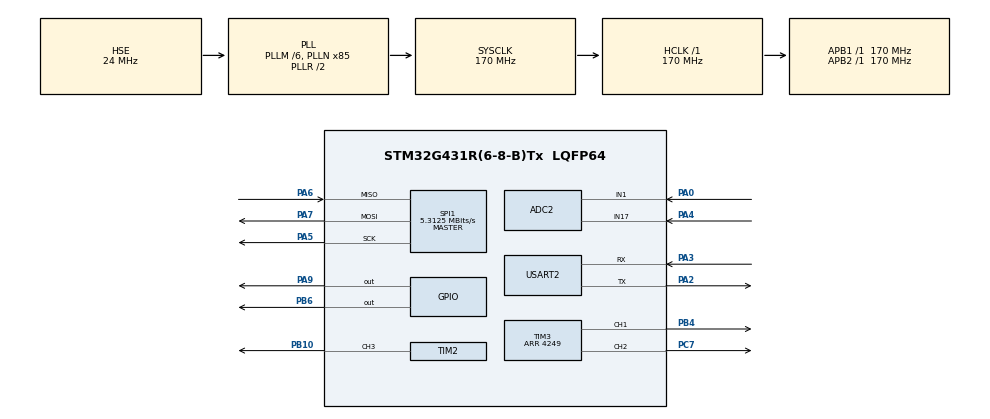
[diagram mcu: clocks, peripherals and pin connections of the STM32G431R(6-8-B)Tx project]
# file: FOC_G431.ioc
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ADC2.Channel-0\#ChannelRegularConversion=ADC_CHANNEL_1
ADC2.Channel-1\#ChannelRegularConversion=ADC_CHANNEL_17
ADC2.DMAContinuousRequests=ENABLE
ADC2.EOCSelection=ADC_EOC_SEQ_CONV
ADC2.ExternalTrigConv=ADC_EXTERNALTRIG_T3_TRGO
ADC2.NbrOfConversion=2
ADC2.NbrOfConversionFlag=1
ADC2.OffsetNumber-0\#ChannelRegularConversion=ADC_OFFSET_NONE
ADC2.OffsetNumber-1\#ChannelRegularConversion=ADC_OFFSET_NONE
ADC2.Rank-0\#ChannelRegularConversion=1
ADC2.Rank-1\#ChannelRegularConversion=2
ADC2.SamplingTime-0\#ChannelRegularConversion=ADC_SAMPLETIME_92CYCLES_5
ADC2.SamplingTime-1\#ChannelRegularConversion=ADC_SAMPLETIME_92CYCLES_5
Dma.ADC2.3.Direction=DMA_PERIPH_TO_MEMORY
Dma.ADC2.3.EventEnable=DISABLE
Dma.ADC2.3.Instance=DMA1_Channel4
Dma.ADC2.3.MemDataAlignment=DMA_MDATAALIGN_HALFWORD
Dma.ADC2.3.MemInc=DMA_MINC_ENABLE
Dma.ADC2.3.Mode=DMA_CIRCULAR
Dma.ADC2.3.PeriphDataAlignment=DMA_PDATAALIGN_HALFWORD
Dma.ADC2.3.PeriphInc=DMA_PINC_DISABLE
Dma.ADC2.3.Polarity=HAL_DMAMUX_REQ_GEN_RISING
Dma.ADC2.3.Priority=DMA_PRIORITY_LOW
Dma.ADC2.3.RequestNumber=1
Dma.ADC2.3.SignalID=NONE
Dma.ADC2.3.SyncEnable=DISABLE
Dma.ADC2.3.SyncPolarity=HAL_DMAMUX_SYNC_NO_EVENT
Dma.ADC2.3.SyncRequestNumber=1
Dma.ADC2.3.SyncSignalID=NONE
Dma.Request0=SPI1_RX
Dma.Request1=SPI1_TX
Dma.Request2=USART2_TX
Dma.Request3=ADC2
Dma.SPI1_RX.0.Direction=DMA_PERIPH_TO_MEMORY
Dma.SPI1_RX.0.EventEnable=DISABLE
Dma.SPI1_RX.0.Instance=DMA1_Channel1
Dma.SPI1_RX.0.MemDataAlignment=DMA_MDATAALIGN_HALFWORD
Dma.SPI1_RX.0.MemInc=DMA_MINC_ENABLE
Dma.SPI1_RX.0.Mode=DMA_NORMAL
Dma.SPI1_RX.0.PeriphDataAlignment=DMA_PDATAALIGN_HALFWORD
Dma.SPI1_RX.0.PeriphInc=DMA_PINC_DISABLE
Dma.SPI1_RX.0.Polarity=HAL_DMAMUX_REQ_GEN_RISING
Dma.SPI1_RX.0.Priority=DMA_PRIORITY_LOW
Dma.SPI1_RX.0.RequestNumber=1
Dma.SPI1_RX.0.SignalID=NONE
Dma.SPI1_RX.0.SyncEnable=ENABLE
Dma.SPI1_RX.0.SyncPolarity=HAL_DMAMUX_SYNC_RISING
Dma.SPI1_RX.0.SyncRequestNumber=1
Dma.SPI1_RX.0.SyncSignalID=NONE
Dma.SPI1_TX.1.Direction=DMA_MEMORY_TO_PERIPH
Dma.SPI1_TX.1.EventEnable=DISABLE
Dma.SPI1_TX.1.Instance=DMA1_Channel2
Dma.SPI1_TX.1.MemDataAlignment=DMA_MDATAALIGN_HALFWORD
Dma.SPI1_TX.1.MemInc=DMA_MINC_ENABLE
Dma.SPI1_TX.1.Mode=DMA_NORMAL
Dma.SPI1_TX.1.PeriphDataAlignment=DMA_PDATAALIGN_HALFWORD
Dma.SPI1_TX.1.PeriphInc=DMA_PINC_DISABLE
Dma.SPI1_TX.1.Polarity=HAL_DMAMUX_REQ_GEN_RISING
Dma.SPI1_TX.1.Priority=DMA_PRIORITY_LOW
Dma.SPI1_TX.1.RequestNumber=1
Dma.SPI1_TX.1.SignalID=NONE
Dma.SPI1_TX.1.SyncEnable=ENABLE
Dma.SPI1_TX.1.SyncPolarity=HAL_DMAMUX_SYNC_RISING
Dma.SPI1_TX.1.SyncRequestNumber=1
Dma.SPI1_TX.1.SyncSignalID=NONE
Dma.USART2_TX.2.Direction=DMA_MEMORY_TO_PERIPH
Dma.USART2_TX.2.EventEnable=DISABLE
Dma.USART2_TX.2.Instance=DMA1_Channel3
Dma.USART2_TX.2.MemDataAlignment=DMA_MDATAALIGN_BYTE
Dma.USART2_TX.2.MemInc=DMA_MINC_ENABLE
Dma.USART2_TX.2.Mode=DMA_NORMAL
Dma.USART2_TX.2.PeriphDataAlignment=DMA_PDATAALIGN_BYTE
Dma.USART2_TX.2.PeriphInc=DMA_PINC_DISABLE
Dma.USART2_TX.2.Polarity=HAL_DMAMUX_REQ_GEN_RISING
Dma.USART2_TX.2.Priority=DMA_PRIORITY_LOW
Dma.USART2_TX.2.RequestNumber=1
Dma.USART2_TX.2.SignalID=NONE
Dma.USART2_TX.2.SyncEnable=DISABLE
Dma.USART2_TX.2.SyncPolarity=HAL_DMAMUX_SYNC_NO_EVENT
Dma.USART2_TX.2.SyncRequestNumber=1
Dma.USART2_TX.2.SyncSignalID=NONE
Mcu.Family=STM32G4
Mcu.Name=STM32G431R(6-8-B)Tx
Mcu.Package=LQFP64
NVIC.DMA1_Channel1_IRQn=true\:2\:0\:true\:false\:true\:false\:true\:true
NVIC.DMA1_Channel2_IRQn=true\:2\:0\:true\:false\:true\:false\:true\:true
NVIC.DMA1_Channel3_IRQn=true\:2\:0\:true\:false\:true\:false\:true\:true
NVIC.DMA1_Channel4_IRQn=true\:0\:0\:false\:false\:true\:false\:true\:true
NVIC.DMAMUX_OVR_IRQn=true\:0\:0\:false\:false\:true\:false\:true\:true
NVIC.PriorityGroup=NVIC_PRIORITYGROUP_4
NVIC.TIM3_IRQn=true\:1\:0\:true\:false\:true\:true\:true\:true
NVIC.USART2_IRQn=true\:3\:0\:true\:false\:true\:true\:true\:true
PA0.Mode=IN1-Single-Ended
PA0.Signal=ADC2_IN1
PA2.Mode=Asynchronous
PA2.Signal=USART2_TX
PA3.Mode=Asynchronous
PA3.Signal=USART2_RX
PA4.Mode=IN17-Single-Ended
PA4.Signal=ADC2_IN17
PA5.Mode=Full_Duplex_Master
PA5.Signal=SPI1_SCK
PA6.Mode=Full_Duplex_Master
PA6.Signal=SPI1_MISO
PA7.Mode=Full_Duplex_Master
PA7.Signal=SPI1_MOSI
PA9.Signal=GPIO_Output
PB10.Signal=S_TIM2_CH3
PB4.Signal=S_TIM3_CH1
PB6.GPIO_ModeDefaultOutputPP=GPIO_MODE_OUTPUT_PP
PB6.PinState=GPIO_PIN_SET
PB6.Signal=GPIO_Output
PC7.Signal=S_TIM3_CH2
PF0-OSC_IN.Mode=HSE-External-Oscillator
PF0-OSC_IN.Signal=RCC_OSC_IN
PF1-OSC_OUT.Mode=HSE-External-Oscillator
PF1-OSC_OUT.Signal=RCC_OSC_OUT
ProjectManager.HeapSize=0x200
ProjectManager.StackSize=0x400
ProjectManager.TargetToolchain=MDK-ARM V5.27
RCC.ADC12Freq_Value=170000000
RCC.AHBFreq_Value=170000000
RCC.APB1Freq_Value=170000000
RCC.APB1TimFreq_Value=170000000
RCC.APB2Freq_Value=170000000
RCC.APB2TimFreq_Value=170000000
RCC.CortexFreq_Value=170000000
RCC.EXTERNAL_CLOCK_VALUE=12288000
RCC.HCLKFreq_Value=170000000
RCC.HSE_VALUE=24000000
RCC.HSI48_VALUE=48000000
RCC.HSI_VALUE=16000000
RCC.LSE_VALUE=32768
RCC.PLLM=RCC_PLLM_DIV6
RCC.PLLN=85
RCC.PLLSourceVirtual=RCC_PLLSOURCE_HSE
RCC.SYSCLKFreq_VALUE=170000000
RCC.SYSCLKSource=RCC_SYSCLKSOURCE_PLLCLK
RCC.USBFreq_Value=170000000
RCC.VCOOutputFreq_Value=340000000
SH.S_TIM2_CH3.0=TIM2_CH3,PWM Generation3 CH3
SH.S_TIM3_CH1.0=TIM3_CH1,PWM Generation1 CH1
SH.S_TIM3_CH2.0=TIM3_CH2,PWM Generation2 CH2
SPI1.BaudRatePrescaler=SPI_BAUDRATEPRESCALER_32
SPI1.CLKPhase=SPI_PHASE_2EDGE
SPI1.CalculateBaudRate=5.3125 MBits/s
SPI1.DataSize=SPI_DATASIZE_16BIT
SPI1.Direction=SPI_DIRECTION_2LINES
SPI1.Mode=SPI_MODE_MASTER
SPI1.VirtualType=VM_MASTER
TIM2.Channel-PWM\ Generation3\ CH3=TIM_CHANNEL_3
TIM2.CounterMode=TIM_COUNTERMODE_CENTERALIGNED1
TIM2.PeriodNoDither=4249
TIM3.Channel-PWM\ Generation1\ CH1=TIM_CHANNEL_1
TIM3.Channel-PWM\ Generation2\ CH2=TIM_CHANNEL_2
TIM3.CounterMode=TIM_COUNTERMODE_CENTERALIGNED1
TIM3.PeriodNoDither=4249
TIM3.TIM_MasterOutputTrigger=TIM_TRGO_UPDATE
USART2.VirtualMode-Asynchronous=VM_ASYNC
VP_SYS_VS_DBSignals.Mode=DisableDeadBatterySignals
VP_TIM2_VS_ClockSourceINT.Mode=Internal
VP_TIM3_VS_ClockSourceINT.Mode=Internal
board=custom

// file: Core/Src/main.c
/* USER CODE BEGIN Header */
/**
  ******************************************************************************
  * @file           : main.c
  * @brief          : Main program body
  ******************************************************************************
  * @attention
  *
  * Copyright (c) 2026 STMicroelectronics.
  * All rights reserved.
  *
  * This software is licensed under terms that can be found in the LICENSE file
  * in the root directory of this software component.
  * If no LICENSE file comes with this software, it is provided AS-IS.
  *
  ******************************************************************************
  */
/* USER CODE END Header */
#include "main.h"
#include "adc.h"
#include "dma.h"
#include "spi.h"
#include "tim.h"
#include "usart.h"
#include "gpio.h"

/* USER CODE BEGIN Includes */
#include <math.h>
#include <stdio.h>
#include "AS5047P.h"
#include "BLDCDriver.h"
#include "HardInit.h"
#include "MotorStat.h"
#include "GetAS5047P.h"
/* USER CODE END Includes */

void SystemClock_Config(void);

int main(void)
{

  /* USER CODE BEGIN 1 */
  // ===== 6-step commutation with rotor alignment =====

  /* USER CODE END 1 */

  /* MCU Configuration--------------------------------------------------------*/

  /* Reset of all peripherals, Initializes the Flash interface and the Systick. */
  HAL_Init();

  /* Configure the system clock */
  SystemClock_Config();

  /* Initialize all configured peripherals */
  MX_GPIO_Init();
  MX_DMA_Init();
  MX_TIM2_Init();
  MX_TIM3_Init();
  MX_SPI1_Init();
  MX_USART2_UART_Init();
  MX_ADC2_Init();
  /* USER CODE BEGIN 2 */
  ALL_Init();

  /* USER CODE END 2 */

  /* Infinite loop */
  while (1)
  {

    /* USER CODE BEGIN 3 */

    AS5047P_StartRead();
    static char tx_buf;
    if (HAL_UART_GetState(&huart2) == HAL_UART_STATE_READY)
    {
        // int len = sprintf(tx_buf, "%d,%d,%d,%d,%d\r\n" ,(int)motor.foc.Vu_Mod,(int)motor.foc.Vv_Mod,(int)motor.foc.Vw_Mod,(int)motor.foc.Theta,(int)Get_Encoder_Abs_Angle_Deg());
        int len = sprintf(tx_buf, "%d,%d\r\n" ,(int)motor.current_sense.adc_buf,(int)motor.current_sense.adc_buf);
        HAL_UART_Transmit_DMA(&huart2, (uint8_t*)tx_buf, len);
    }
  }
  /* USER CODE END 3 */
}

void SystemClock_Config(void)
{
  RCC_OscInitTypeDef RCC_OscInitStruct = {0};
  RCC_ClkInitTypeDef RCC_ClkInitStruct = {0};

  /** Configure the main internal regulator output voltage
  */
  HAL_PWREx_ControlVoltageScaling(PWR_REGULATOR_VOLTAGE_SCALE1_BOOST);

  /** Initializes the RCC Oscillators according to the specified parameters
  * in the RCC_OscInitTypeDef structure.
  */
  RCC_OscInitStruct.OscillatorType = RCC_OSCILLATORTYPE_HSE;
  RCC_OscInitStruct.HSEState = RCC_HSE_ON;
  RCC_OscInitStruct.PLL.PLLState = RCC_PLL_ON;
  RCC_OscInitStruct.PLL.PLLSource = RCC_PLLSOURCE_HSE;
  RCC_OscInitStruct.PLL.PLLM = RCC_PLLM_DIV6;
  RCC_OscInitStruct.PLL.PLLN = 85;
  RCC_OscInitStruct.PLL.PLLP = RCC_PLLP_DIV2;
  RCC_OscInitStruct.PLL.PLLQ = RCC_PLLQ_DIV2;
  RCC_OscInitStruct.PLL.PLLR = RCC_PLLR_DIV2;
  if (HAL_RCC_OscConfig(&RCC_OscInitStruct) != HAL_OK)
  {
    Error_Handler();
  }

  /** Initializes the CPU, AHB and APB buses clocks
  */
  RCC_ClkInitStruct.ClockType = RCC_CLOCKTYPE_HCLK|RCC_CLOCKTYPE_SYSCLK
                              |RCC_CLOCKTYPE_PCLK1|RCC_CLOCKTYPE_PCLK2;
  RCC_ClkInitStruct.SYSCLKSource = RCC_SYSCLKSOURCE_PLLCLK;
  RCC_ClkInitStruct.AHBCLKDivider = RCC_SYSCLK_DIV1;
  RCC_ClkInitStruct.APB1CLKDivider = RCC_HCLK_DIV1;
  RCC_ClkInitStruct.APB2CLKDivider = RCC_HCLK_DIV1;

  if (HAL_RCC_ClockConfig(&RCC_ClkInitStruct, FLASH_LATENCY_4) != HAL_OK)
  {
    Error_Handler();
  }
}

void Error_Handler(void)
{
  __disable_irq();
  while (1)
  {
  }
}
